# YTM32B1HA0 register map
Vendor: YTMicro; File version: 1.0
CPU: little endian, MPU, FPU, 2 interrupt priority bits
Registers are 32-bit, read-write, reset 0x0 unless marked. A register's access mark holds for its fields unless they carry their own. Offsets are from the block's base; [hi:lo] are bit positions; {n}, {i} and the like mark numbered series; 'fields as' and 'values as' point back to an identical list.

## LINFlexD0
Base 0x4006C000; register names take the prefix LINFlexD0_
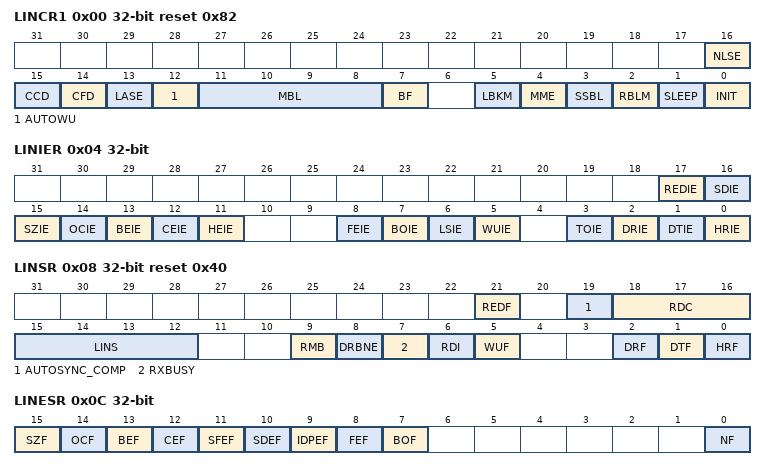
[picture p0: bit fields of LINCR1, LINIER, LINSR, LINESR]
0x00 LINCR1 reset 0x82 — The LINCR1 register consists of control bits used to configure features of the LINFlexD. ote{When accessing the LINCR1 register, each reserved bit should be written with its original reset value.}
  [16] NLSE — NLSE enables/disables capture of the LIN state (LINSR.LINS) whenever a bit error flag occurs (LINESR.BEF is set to 1).
    0=LINSR.LINS shows the current LIN state and does not capture the LIN state on bit error; 1=LINSR.LINS is captured when a bit error flag occurs
  [15] CCD
    0=Checksum calculation is done by hardware. The LINCFR register is read-only.; 1=Checksum calculation is disabled. The LINCFR register is read/write. If the checksum field is enabled (CFD = 0), LINCFR can be programmed to send a software-calculated checksum/CRC.
  [14] CFD
    0=Checksum field is sent after the required number of data bytes are sent; 1=No checksum field is sent in the frame
  [13] LASE — Enables the autosynchronization, feature described in “Automatic Resynchronization”.
    0=Disable autosynchronization; 1=Enable autosynchronization
  [12] AUTOWU
    0=The SLEEP bit is cleared by software only; 1=The SLEEP bit is cleared by hardware whenever the LINSR.WUF bit is set
  [11:8] MBL — Controls the length of the break field generated in LIN master mode.
    {v}={v+10}-bit break length (v=0..13); 14=36-bit break length; 15=50-bit break length
  [7] BF — Controls the receive filter bypass function.
    0=Receiver ignores incoming frame if ID does not match any ID filter or if no ID filters are active; 1=If no ID filters are active, receiver responds to incoming frames. If ID filters are active, receiver responds if frame is received but does not match any filter.
  [5] LBKM — Enables or disables Loop Back mode as described in “Loop Back Mode”.
    0=Disable Loop Back mode; 1=Enable Loop Back mode
  [4] MME
    0=Slave mode; 1=Master mode
  [3] SSBL — Sets the number of bit times for break field detection in slave mode.
    0=11-bit break length; 1=10-bit break length
  [2] RBLM
    0=Receiver is buffer is not locked. The next incoming message overwrites the previous one.; 1=Receiver buffer is locked against overrun. Once the buffer is full, the next incoming message is discarded if the buffer is not released by software clearing the LINSR.RMB bit.
  [1] SLEEP — Set by software to request LINFlexD to enter Sleep mode. ewline The SLEEP bit is cleared by software to exit sleep mode. ewline If LINCR1.AUTOWU and LINSR.WUF are set, SLEEP is automatically cleared by hardware to exit sleep mode. ewline SLEEP is effective in both LIN and UART modes.
  [0] INIT — Set by software to switch the hardware into Initialization mode. ewline When software clears the INIT bit (and if the SLEEP bit is also 0), the LINFlexD enters Normal mode. ewline INIT is effective in both LIN and UART modes.
0x04 LINIER
  [17] REDIE
    0=Interrupt disabled; 1=Interrupt enabled. An interrupt is generated when the Receive Edge Detection Flag (REDF) is set in LINSR.
  [16] SDIE
    0=Interrupt disabled; 1=Interrupt enabled. An interrupt is generated when the Start Detection Flag (SDF) is set in LINSR.
  [15] SZIE
    0=Interrupt disabled; 1=Interrupt enabled. An interrupt is generated when the Stuck at Zero Flag (SZF) is set in LINESR or UARTSR.
  [14] OCIE
    0=Interrupt disabled; 1=Interrupt enabled. An interrupt is generated when the Output Compare Flag (OCF) is set in LINESR or UARTSR.
  [13] BEIE
    0=Interrupt disabled; 1=Interrupt enabled. An interrupt is generated when the Bit Error Flag (BEF) is set in LINESR.
  [12] CEIE
    0=Interrupt disabled; 1=Interrupt enabled. An interrupt is generated when the Checksum Error Flag (CEF) is set in LINESR.
  [11] HEIE
    0=Interrupt disabled; 1=Interrupt enabled. An interrupt is generated when the any of the following flags are set in LINESR: SFEF, SDEF, IDPEF.
  [8] FEIE
    0=Interrupt disabled; 1=Interrupt enabled. An interrupt is generated when the Frame Error Flag (FEF) is set in LINESR or UARTSR.
  [7] BOIE
    0=Interrupt disabled; 1=Interrupt enabled. An interrupt is generated when the Buffer Overrun Flag (BOF) is set in LINESR or UARTSR.
  [6] LSIE
    0=Interrupt disabled; 1=Interrupt enabled. An interrupt generated on entering the following states: Sync Del, Sync Field, Identifier Field, Checksum.
  [5] WUIE
    0=Interrupt disabled; 1=Interrupt enabled. An interrupt generated when the Wakeup Flag (WUF) is set in LINESR or UARTSR.
  [3] TOIE
    0=Interrupt disabled; 1=Interrupt enabled. An interrupt generated when the LINFlexD is in UART mode and the Timeout bit (TO) is set in UARTSR.
  [2] DRIE
    0=Interrupt disabled; 1=Interrupt enabled. An interrupt generated when the Data Received Flag (DRF) is set in LINESR or UARTSR.
  [1] DTIE
    0=Interrupt disabled; 1=Interrupt enabled. An interrupt generated when the Data Transmitted Flag (DTF) is set in LINESR or UARTSR.
  [0] HRIE
    0=Interrupt disabled; 1=Interrupt enabled. An interrupt is generated Header Received Flag (HRF) is set in LINSR.
0x08 LINSR reset 0x40 — The LINSR register contains status bits indicating the state of the LINFlexD hardware. ote{Reset value of RDI reflects the LINFlexD_RX pin state.}
  [21] REDF — REDF is set by hardware when receiving falling edge is detected.
  [19] AUTOSYNC_COMP — AUTOSYNC_COMP is set when autosynchronization is enabled (LINCR1.LASE is set) and autosynchronization is complete. After AUTOSYNC_COMP is set, the contents of LINIBRR and LINFBRR registers can be read.
  [18:16] RDC ro — RDC contains the number of entries (bytes) in the receive data buffer in LIN mode.
    0=1 byte; {v}={v+1} bytes (v=1..7)
  [15:12] LINS ro
  [9] RMB
    0=Buffer is free; 1=Buffer data is ready to be read by software. RMB should be cleared by software after reading the data received in the buffer.
  [8] DRBNE — DRBNE is set by hardware as soon as the first byte of response is received and stored in DATA (when there is at least one data byte in reception buffer). Software should clear DRBNE after reading all the buffers. ewline DRBNE can be checked by software in the case of a response timeout event. ewline DRBNE is cleared by hardware in Initialization mode.
  [7] RXBUSY ro
    0=Receiver is idle; 1=Reception is ongoing
  [6] RDI ro — Indicates the current state of the LINFlexD_RX pin. ote{After reset is released, RDI reflects the actual value of the LINFlexD_RX pin.}
  [5] WUF — WUF is set by hardware when a falling edge is detected on the LINFlexD_RX pin in either of the following conditions: \begin{itemize}[] \item The LINFlexD is in slave mode and in Sleep mode. \item The LINFlexD is in master mode is in either Sleep mode or Idle state. \end{itemize} WUF is cleared by hardware in Initialization mode.
  [2] DRF — DRF is set by hardware and indicates that data reception has completed. ewline DRF is cleared by hardware in Initialization mode. ote{DRF is not set when a framing error or checksum error occurs.}
  [1] DTF — DTF is set by hardware and indicates that data transmission has completed. ewline DTF is cleared by hardware in Initialization mode. ote{DTF is not set in LIN mode when a bit error occurs and LINCR2.IOBE = 0.}
  [0] HRF — HRF is set by hardware when header reception completes and one of the following conditions is true. \begin{itemize}[] \item All filters are inactive and LINCR1.BF = 1. \item No match in any filter and LINCR1.BF = 1. \item Tx filter match. \end{itemize} HRF is reset by hardware in Initialization mode and at end of completed or aborted frame.
0x0C LINESR — The LINESR register contains status bits for various error conditions. For detailed descriptions the error conditions, see \hyperlink{errors}{“Errors”}.
  [15] SZF — Set by hardware when a stuck-at-zero timeout error occurs.
  [14] OCF — In master mode, OCF is set when counter LINTCSR.CNT matches the content of LINOCR.OC2. ewline In slave mode, OCF is set when the content of the counter LINTCSR.CNT matches the content of LINOCR.OC1 or LINOCR.OC2. ewline If OCF is set when LINTCSR.MODE = 0 and LINTCSR.IOT = 1, the LINFlexD goes to Idle state. ewline When LINTCSR.MODE = 0, OCF is cleared by hardware in Initialization mode. ewline When LINTCSR.MODE = 1, OCF maintains its status regardless of the LIN state.
  [13] BEF — BEF is set by hardware when the LINFlexD detects a bit error. ewline BEF is cleared by hardware in Initialization mode.
  [12] CEF — CEF is set by hardware when the received checksum does not match the hardware calculated checksum. ewline CEF is cleared by hardware in Initialization mode. ote{CEF is never set if LINCR1.CCD or LINCR1.CFD is set.}
  [11] SFEF — SFEF is set by hardware when a sync field error occurs due to an inconsistent sync field. ewline SFEF is cleared by hardware in Initialization mode.
  [10] SDEF — SDEF is set by hardware when a break delimiter error occurs because a break delimiter is too short (less than one bit time). ewline SDEF is cleared by hardware in Initialization mode.
  [9] IDPEF — IDPEF is set by hardware LINFlexD detects an error in the ID parity. ewline IDPEF is cleared by hardware in Initialization mode.
  [8] FEF — FEF is set by hardware when a framing error (invalid stop bit) occurs. ewline FEF is cleared by hardware in Initialization mode.
  [7] BOF — BOF is set by hardware when a new byte is received and LINSR.RMB bit is not cleared. ewline BOF is cleared by hardware in Initialization mode.
  [0] NF — NF is set by hardware when noise is detected in a receive character. ewline NF is cleared by hardware in Initialization mode.
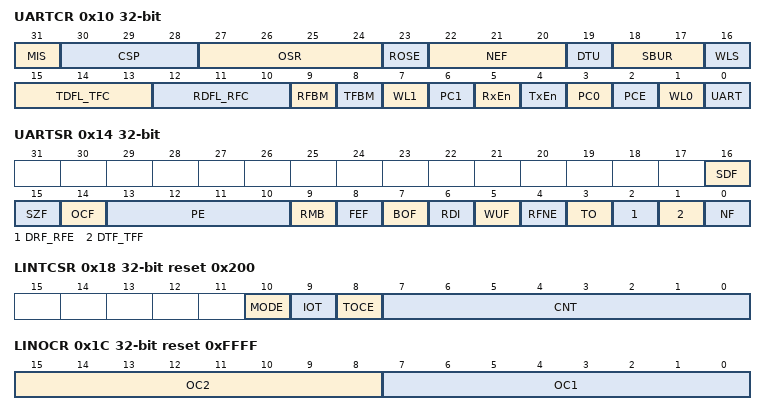
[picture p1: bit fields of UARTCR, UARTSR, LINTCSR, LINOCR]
0x10 UARTCR — The UARTCR register contains control bits for UART mode. ote{Always write ‘0’ to reserved bits when writing to UARTCR.} ote{In UART mode, the LINFlexD does not support communication with Special Word Length (UARTCR.WLS = 1) in buffer mode.} ote{In UART mode, the LINFlexD supports communication with Special Word Length (UARTCR.WLS = 1) in FIFO mode only with UARTCR.WL[1:0] = 11.}
  [31] MIS
    0=UARTCTO monitors the number of bits to be received; 1=UARTCTO monitors the idle state of the reception line
  [30:28] CSP — The CSP bits select the sample point during reduced oversampling. ewline CSP can have the following range of values for the specified oversampling rate:
  [27:24] OSR — Selects the number of samples taken for a bit when reduced oversampling is enabled. ewline The values allowed for OSR are 4, 5, 6, and 8. ote{When idle state monitoring is enabled (MIS = 1), the allowed OSR values are 4 and 8.} OSR can be read in any mode, but can be written only during Initialization mode.
  [23] ROSE
    0=Each bit is oversampled sixteen times; 1=OSR bits determine the oversampling rate
  [22:20] NEF — The NEF bits set the number of expected frames in UART reception mode. If the DTU bit is set, then the UART timeout counter is reset after the configured number of frames have been received. ewline NEF can be read in any mode, but can be written only during Initialization mode.
  [19] DTU
    0=Timeout must be handled by software; 1=Timeout in UART mode is disabled after the configured number of data frames are received
  [18:17] SBUR
    0=1 stop bit; 1=2 stop bits; 2=3 stop bits
  [16] WLS
    0=Disable 12-bit + parity bit in reception; 1=Enable 12-bit + parity bit in reception (UART mode)
  [15:13] TDFL_TFC — The TDFL_TFC field has one of two functions depending on the mode of operation. ewline extbf{UART Buffer Mode:} ewline When the LINFlexD is in UART buffer mode (TFBM = 0), TDFL_TFC is read/write and defines the number of bytes to be transmitted. \begin{itemize}[] \item x00: 1 byte \item x01: 2 bytes \item x10: 3 bytes \item x11: 4 bytes \end{itemize} The first bit is reserved and not implemented. ewline When the UART data length is configured as half-word (WL = 10 or 11), the only valid values for TDFL_TFC are x01 and x11. ewline extbf{UART FIFO Mode:} ewline When the LINFlexD is in UART FIFO mode (TFBM = 1), TDFL_TFC is read-only and contains the number of entries (bytes) in the Tx FIFO. \begin{itemize}[] \item 000: Empty \item 001: 1 byte \item 010: 2 bytes \item 011: 3 bytes \item 100: 4 bytes \item All other values: Reserved \end{itemize} TDFL_TFC can be read in any mode, but can be written only during Initialization mode, when the UART bit is set.
  [12:10] RDFL_RFC — The RDFL_RFC field has one of two functions depending on the mode of operation. ewline extbf{UART Buffer Mode:} ewline When the LINFlexD is in UART buffer mode (RFBM = 0), RDFL_RFC is read/write and defines the number of bytes to be received: \begin{itemize}[] \item x00: 1 byte \item x01: 2 bytes \item x10: 3 bytes \item x11: 4 bytes \end{itemize} The first bit is reserved and not implemented. ewline When the UART data length is configured as half-word (WL = 10 or 11), the only valid values for RDFL_RFC are x01 and x11. ewline RDFL_RFC should be programmed to be greater than or equal to NEF (number of expected frames). ewline extbf{UART FIFO Mode:} ewline When the LINFlexD is in UART FIFO mode (RFBM = 1), RDFL_RFC is read-only and contains the number of entries (bytes) in the Rx FIFO: \begin{itemize}[] \item 000: Empty \item 001: 1 byte \item 010: 2 bytes (1.5 byte if WLS = 1) \item 011: 3 bytes \item 100: 4 bytes (2x1.5 bytes if WLS = 1) \item All other values: Reserved \end{itemize} RDFL_RFC can be read in any mode, but can be written only during Initialization mode, when the UART bit is set.
  [9] RFBM
    0=Rx buffer mode enabled; 1=Rx FIFO mode enabled (mandatory in DMA Rx mode)
  [8] TFBM
    0=Tx buffer mode enabled; 1=Tx FIFO mode enabled (mandatory in DMA Tx mode)
  [7] WL1
  [6] PC1
  [5] RxEn
    0=Receiver disabled; 1=Receiver enabled
  [4] TxEn
    0=Transmitter disabled; 1=Transmitter enabled
  [3] PC0
  [2] PCE
    0=Parity transmit/check disabled; 1=Parity transmit/check enabled
  [1] WL0
  [0] UART
    0=LIN mode; 1=UART mode
0x14 UARTSR — The UARTSR register contains status bits for UART mode.
  [16] SDF — SDF is set by hardware when receiving start bit is detected.
  [15] SZF — SZF is set by hardware when 100 dominant bits are detected. An interrupt is generated if LINIER.SZIE = 1. ewline SZF reflects the same value as LINESR.SZF when the LINFlexD is not in Initialization mode and UARTCR.UART = 1.
  [14] OCF
    0=No output compare event occurred; 1=The content of the timeout counter matched the content of LINOCR
  [13:10] PE — Indicates parity error in corresponding receive data byte.
    0=No parity error detected; 1=Parity error detected
  [9] RMB
    0=Buffer is free; 1=Buffer data is ready to be read by software
  [8] FEF — FEF is set by hardware when the LINFlexD detects a framing error (invalid stop bit). An interrupt is generated if LINIER.FEIE = 1. ewline FEF reflects the same value as LINESR.FEF when the LINFlexD is not in Initialization mode and UARTCR.UART = 1.
  [7] BOF — In UART buffer mode, BOF is set by hardware when there is a new byte received and the RMB bit is not cleared. If LINCR.RBLM = 1, the newly received message is discarded. If LINCR.RBLM = 0, the newly received message overwrites the buffer. ewline In UART FIFO mode, BOF is set when there is a new byte received and the Rx FIFO is full. In UART FIFO mode, once Rx FIFO is full, the new received message is discarded regardless of the value of the RBLM bit. ewline When BOF is set, an interrupt is generated if LINIER.BOIE = 1. ewline BOF reflects the same value as LINESR.BOF when the LINFlexD is not in Initialization mode and UARTCR.UART = 0.
  [6] RDI ro — Reflects the current state of the LINFlexD_RX pin when UARTCR.UART = 1
  [5] WUF — WUF is set by hardware when a falling edge is detected on the LINFlexD_RX pin in Sleep mode. An interrupt is generated if LINIER.WUIE = 1. ewline WUF reflects the same value as LINSR.WUF when the LINFlexD is not in Initialization mode and UARTCR.UART = 1.
  [4] RFNE ro — RFNE is set by hardware in UART FIFO mode (RFBM = 1), when there is at least one data byte present in the receive FIFO. RFNE is a read-only bit for debugging purposes. ewline RFNE can be used by software in case of a timeout event.
  [3] TO — TO is set by hardware when a UART timeout occurs — in other words, the value of UARTCTO becomes equal to the preset value of the timeout (UARTPTO register setting). An interrupt is generated if LINIER.TOIE = 1. ewline The GCR.SR bit should be used to reset the receiver FSM to the Idle state in the event of timeout for UART reception in both UART buffer and UART FIFO modes.
  [2] DRF_RFE — The DRF_RFE bit function depends on whether the LINFlexD is operating in UART buffer mode or UART FIFO mode. ewline extbf{UART Buffer Mode:} ewline In UART buffer mode (RFBM = 0), the DRF (data received flag) function of DRF_RFE is used. DRF is set by hardware in UART buffer mode when the number of bytes programmed in UARTCR.RDFL are received. An interrupt is generated if LINIER.DRIE = 1. ewline DRF is set when the configured number of valid stop bits are received for the last frame. ewline DRF is set regardless of parity error, overrun error, or framing error if the framing error is in the last STOP bit configured. ewline DRF reflects the same value as LINSR.DRF when the LINFlexD is not in Initialization mode and UARTCR.UART = 1. ewline DRF can be read/cleared by software. Writing ‘1’ clears DRF. ewline extbf{UART FIFO Mode:} ewline In UART FIFO mode (RFBM = 1), the RFE (Rx FIFO empty) function of DRF_RFE is used. RFE is set by hardware in UART FIFO mode when the Rx FIFO is empty. ewline RFE is a read-only bit for debugging purposes. It is internally used by the DMA Rx interface.
  [1] DTF_TFF — The DTF_TFF bit function depends on whether the LINFlexD is operating in UART buffer mode or UART FIFO mode. ewline extbf{UART Buffer Mode:} ewline In UART buffer mode (RFBM = 0), the DTF (data transmitted flag) function of DTF_TFF is used. DTF is set by hardware in UART buffer mode when data transmission completes. An interrupt is generated if LINIER.DTIE = 1. ewline DTF reflects the same value as LINSR.DTF when the LINFlexD is not in Initialization mode and UARTCR.UART = 1. ewline DTF can be read/cleared by software. Writing ‘1’ clears DTF. ewline extbf{UART FIFO Mode:} ewline In UART FIFO mode (RFBM = 1), the TFF (Tx FIFO full) function of DTF_TFF is used. TFF is set by hardware in UART FIFO mode when Tx FIFO is full. ewline TFF is a read-only bit for debugging purposes. It is internally used by the DMA Tx interface.
  [0] NF — Set by hardware when noise is detected in the received character. ewline NF reflects the same value as LINESR.NF when the LINFlexD is not in Initialization mode and the UARTCR.UART = 1. ewline During reduced oversampling (UARTCR.ROSE = 1), the NF bit is enabled only when UARTCR.OSR = 8.
0x18 LINTCSR reset 0x200 — The LINTCSR register contains control and status bits for the LIN timeout feature. ote{When LINTCSR.MODE = 0, any activity on the transmit or receive pins will cause an unwanted change in the value of the 8-bit field Output Compare Value 2 (OC2) of the LIN Output Compare register (LINOCR). If the LINFlexD is enabled in LIN mode and the value of LINTCSR.MODE is changed from ‘1’ to ‘0’, the old values of LINOCR.OC1 and LINOCR.OC2 are retained. As a consequence, if the LINFlexD is reconfigured from UART mode to LIN mode, or LINTCSR.MODE is changed from ‘1’ to ‘0’, an incorrect timeout exception is generated when a LIN communication starts. To avoid this, set LINTCSR.MODE to ‘1’, reconfigure the LINFlexD in LIN mode, then reset LINTCSR.MODE to ‘0’. Before switching LINTCSR.MODE from ‘1’ to ‘0’ between frames, load LINOCR with 0xFFFF.}
  [10] MODE
    0=LIN mode; 1=Output compare mode
  [9] IOT
    0=LIN state machine does not reset to Idle on timeout; 1=LIN state machine resets to Idle on timeout event
  [8] TOCE
    0=Timeout counter disabled. UARTSR.OCF flag is not set on an output compare event.; 1=Timeout counter enabled. UARTSR.OCF is set if an output compare event occurs.
  [7:0] CNT ro — The value of the timeout counter. ote{For proper functionality of this counter, LINIBRR should be greater than or equal to 5.}
0x1C LINOCR reset 0xFFFF — The LINOCR register contains the value to be compared to the LINTCSR.CNT value. ewline LINOCR is writable by software only in when the counter is in output compare mode.
  [15:8] OC2, [7:0] OC1
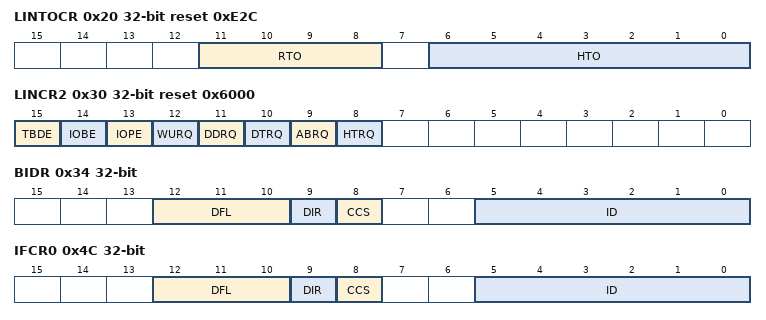
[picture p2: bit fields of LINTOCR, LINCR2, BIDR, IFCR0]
0x20 LINTOCR reset 0xE2C — The LINTOCR register contains the LIN mode response and header timeout values.
  [11:8] RTO
  [6:0] HTO — HTO specifies the header timeout duration (in bit time). HTO can be written only for slave mode. The header timeout should be programmed without considering 11 bits of break field.
0x24 LINFBRR — LINFBRR sets the fractional part of the LIN baud rate, as described in \hyperlink{baud-rate-generation}{“Baud Rate Generation”}. ote{When LINCR1.LASE = 1, LINFBRR should be read only after LINSR.AUTOSYNC_COMP is set to obtain the correct value.} ote{LINFBRR cannot be used when reduced oversampling is enabled (UARTCR.ROSE = 1).}
  [3:0] FBR
    0=Fraction(LDIV) = 0; {v}=Fraction(LDIV) = {v}/16 (v=1..15)
0x28 LINIBRR — LINIBRR sets the integer part of the LIN baud rate, as described in \hyperlink{baud-rate-generation}{“Baud Rate Generation”}. ote{When LINCR1.LASE = 1, LINIBRR should be read only after LINSR.AUTOSYNC_COMP is set to obtain the correct value.}
  [19:0] IBR — The IBR bits, along with the fractional baud rate bits in LINFBRR, set the LIN baud rate. \begin{itemize}[] \item IBR = 0x0: LIN clock disabled \item IBR = 0x1: Mantissa(LDIV) = 1 \item ... \item IBR = 0xFFFFE: Mantissa(LDIV) = 1048574 \item IBR = 0xFFFFF: Mantissa(LDIV) = 1048575 \end{itemize} IBR can be read in any mode, but can be written only during Initialization mode.
0x2C LINCFR — ote{There is a delay between 4 to 6 clock cycles of bus clock for the internal checksum’s value (which is clocked with ipg_baud_clk/16 * LDIV) to reflect on LINCFR.} ote{Due to synchronization structures between the two input clocks to the LINFlexD, the write to this register is delayed between 2 to 3 clock cycles of bus clock.}
  [7:0] CF — When LINCR1.CCD = 0, the CF bits are read-only and are calculated by hardware. ewline When LINCR1.CCD = 1, the CF bits can be written by software.
0x30 LINCR2 reset 0x6000 — The LINCR2 register contains control and status bits related to buffer operations. ote{When accessing LINCR2, each reserved bit should be written with its original reset value.}
  [15] TBDE
    0=Delimiter length in break field is 1 bit; 1=Delimiter length in break field is 2 bits
  [14] IOBE
    0=Bit error does not reset LIN state machine; 1=Bit error resets LIN state machine
  [13] IOPE
    0=Parity error does not reset LIN state machine; 1=Parity error resets LIN state machine
  [12] WURQ — Setting WURQ generates a wakeup request. The character sent during wakeup is copied from DATA0. WURQ is reset by hardware when the wakeup character has been transmitted. ewline WURQ cannot be set in Sleep mode. Software must exit Sleep mode before setting WURQ. ewline Bit error is not checked when transmitting the wakeup request.
  [11] DDRQ — DDRQ is set by software to stop data reception if the frame does not concern the node. DDRQ is reset by hardware once the LINFlexD ignores the response and moves to Idle state. ewline For a LIN slave, DDRQ can be set only when LINSR.HRF = 1 and the identifier is software-filtered.
  [10] DTRQ — DTRQ is set by software in slave mode to request the transmission of the LIN data field stored in the buffer data register. DTRQ can be set only when LINSR.HRF = 1 (to ensure that data transmission is requested only after a header reception). ewline DTRQ is cleared by hardware when the request has been completed, or on abort request or error condition. ewline In master mode, DTRQ is set by hardware when BIDR.DIR = 1 and header transmission is complete.
  [9] ABRQ — ABRQ is set by software to abort the current transmission. The LINFlexD aborts the transmission at the end of the current bit. ewline ABRQ is cleared by hardware when the transmission has been aborted. ewline ABRQ can abort a wakeup request and can also be used in UART mode.
  [8] HTRQ — HTRQ is set by software to request the transmission of a LIN header. ewline HTRQ is cleared by hardware when the request has been completed or on abort request. ewline HTRQ has no effect in UART mode. ote{In master mode, if both HTRQ and ABRQ are set at the same time then ABRQ has no effect. Similarly, in slave mode after header reception, if DTRQ and ABRQ are simultaneously set then ABRQ has no effect.}
0x34 BIDR — The BIDR register contains bits that provide information about the identifier of the transaction and other related information. ote{All the fields (ID, CSS, DIR, DFL) of the BIDR register must be updated when an ID filter (enabled) in Slave mode (Tx or Rx) matches the ID received.}
  [12:10] DFL — Number of data bytes in the response part of the frame. ewline DFL = Number of data bytes - 1.
  [9] DIR — Controls the direction of the data field.
    0=LINFlexD receives the data and copies it to the DATA registers; 1=LINFlexD transmits the data from the DATA registers
  [8] CCS — Controls the type of checksum applied on the current message.
    0=Enhanced checksum covering identifier and data fields. This is compatible with LIN specification rev. 2.0 and higher.; 1=Classic checksum covering data field only. This is compatible with LIN specification rev. 1.3 and lower.
  [5:0] ID — Identifier part of the identifier field without the identifier parity. ewline The ID field can be written only in master mode (LINCR1.MME = 1).
0x38 DATA8 8-bit
  [7:0] DATA — Byte of the data field.
0x40 IFER — The IFER register enables/disables the identifier filters. There is one filter active (FACT) bit for each filter.
  [15:0] FACT — One bit for each identifier filter. ewline Software sets FACT[n] to activate the filter n in identifier list mode. ewline In identifier mask mode, FACT[2n+1] have no effect on the corresponding filters as they act as mask for identifier 2n. ewline FACT[n] can be read in any mode, but can be written only during Initialization mode.
0x44 IFMI ro — The IFMI register contains the index corresponding to the received identifier. It can be used to read or write the data directly in RAM.
  [4:0] IFMI — Contains the index corresponding to the received identifier. ewline Upon a filter match with filter x, IFMI[N:0] = x+1. ewline On no match, IFMI is equal to 0x00. ewline IFMI can be used to directly write or read the data in RAM (see \hyperlink{slave-mode}{“Slave Mode”} for details).
0x48 IFMR — The IFMR register configures the modes of filters. There is one IFM bit for each pair of filters.
  [7:0] IFM — \begin{itemize}[] \item 0: Filters 2n and 2n+1 are in identifier list mode. \item 1: Filters 2n and 2n+1 are in mask mode. Filter 2n+1 is the mask for filter 2n. \end{itemize} IFM[n] can be read in any mode, but can be written only during Initialization mode.
0x4C IFCR0 — There is an Identifier Filter Control Register (IFCRn) for each filter. ewline Even-numbered instances of IFCRn (IFCR0, IFCR2, IFCR4, and so on) act as filters in both identifier list and identifier mask modes. ewline Odd-numbered instances of IFCRn (IFCR1, IFCR3, IFCR5, and so on) act as: \begin{itemize}[] \item Filters in identifier list mode. \item A mask for the preceding-numbered register in identifier mask mode. For example, if filters 0 and 1 are configured for identifier mask mode, IFCR1 acts as a mask for IFCR0. \end{itemize} The IFCRn registers are read-only in Normal mode and can be written only in Initialization mode.
  [12:10] DFL — Number of data bytes in the response part of the frame. ewline DFL = Number of data bytes - 1.
  [9] DIR — Controls the direction of the data field.
    0=LINFlexD receives the data and copy it to the DATA registers; 1=LINFlexD transmits the data from the DATA register
  [8] CCS — Controls the type of checksum applied on the current message.
    values as BIDR.CCS
  [5:0] ID — Identifier part of the identifier field without the identifier parity.
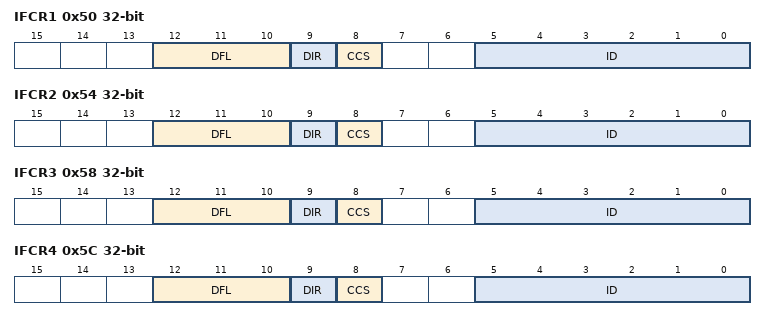
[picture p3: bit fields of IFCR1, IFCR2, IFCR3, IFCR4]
0x50 IFCR1 — There is an Identifier Filter Control Register (IFCRn) for each filter. ewline Even-numbered instances of IFCRn (IFCR0, IFCR2, IFCR4, and so on) act as filters in both identifier list and identifier mask modes. ewline Odd-numbered instances of IFCRn (IFCR1, IFCR3, IFCR5, and so on) act as: \begin{itemize}[] \item Filters in identifier list mode. \item A mask for the preceding-numbered register in identifier mask mode. For example, if filters 0 and 1 are configured for identifier mask mode, IFCR1 acts as a mask for IFCR0. \end{itemize} The IFCRn registers are read-only in Normal mode and can be written only in Initialization mode.
  fields as IFCR0
0x54 IFCR2 — There is an Identifier Filter Control Register (IFCRn) for each filter. ewline Even-numbered instances of IFCRn (IFCR0, IFCR2, IFCR4, and so on) act as filters in both identifier list and identifier mask modes. ewline Odd-numbered instances of IFCRn (IFCR1, IFCR3, IFCR5, and so on) act as: \begin{itemize}[] \item Filters in identifier list mode. \item A mask for the preceding-numbered register in identifier mask mode. For example, if filters 0 and 1 are configured for identifier mask mode, IFCR1 acts as a mask for IFCR0. \end{itemize} The IFCRn registers are read-only in Normal mode and can be written only in Initialization mode.
  fields as IFCR0
0x58 IFCR3 — There is an Identifier Filter Control Register (IFCRn) for each filter. ewline Even-numbered instances of IFCRn (IFCR0, IFCR2, IFCR4, and so on) act as filters in both identifier list and identifier mask modes. ewline Odd-numbered instances of IFCRn (IFCR1, IFCR3, IFCR5, and so on) act as: \begin{itemize}[] \item Filters in identifier list mode. \item A mask for the preceding-numbered register in identifier mask mode. For example, if filters 0 and 1 are configured for identifier mask mode, IFCR1 acts as a mask for IFCR0. \end{itemize} The IFCRn registers are read-only in Normal mode and can be written only in Initialization mode.
  fields as IFCR0
0x5C IFCR4 — There is an Identifier Filter Control Register (IFCRn) for each filter. ewline Even-numbered instances of IFCRn (IFCR0, IFCR2, IFCR4, and so on) act as filters in both identifier list and identifier mask modes. ewline Odd-numbered instances of IFCRn (IFCR1, IFCR3, IFCR5, and so on) act as: \begin{itemize}[] \item Filters in identifier list mode. \item A mask for the preceding-numbered register in identifier mask mode. For example, if filters 0 and 1 are configured for identifier mask mode, IFCR1 acts as a mask for IFCR0. \end{itemize} The IFCRn registers are read-only in Normal mode and can be written only in Initialization mode.
  fields as IFCR0
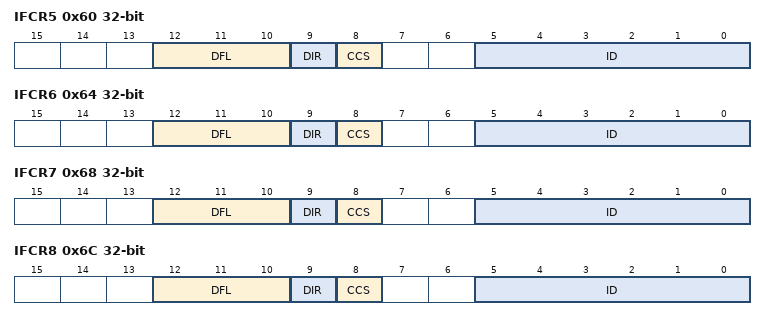
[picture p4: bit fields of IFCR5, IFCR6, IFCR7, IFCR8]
0x60 IFCR5 — There is an Identifier Filter Control Register (IFCRn) for each filter. ewline Even-numbered instances of IFCRn (IFCR0, IFCR2, IFCR4, and so on) act as filters in both identifier list and identifier mask modes. ewline Odd-numbered instances of IFCRn (IFCR1, IFCR3, IFCR5, and so on) act as: \begin{itemize}[] \item Filters in identifier list mode. \item A mask for the preceding-numbered register in identifier mask mode. For example, if filters 0 and 1 are configured for identifier mask mode, IFCR1 acts as a mask for IFCR0. \end{itemize} The IFCRn registers are read-only in Normal mode and can be written only in Initialization mode.
  fields as IFCR0
0x64 IFCR6 — There is an Identifier Filter Control Register (IFCRn) for each filter. ewline Even-numbered instances of IFCRn (IFCR0, IFCR2, IFCR4, and so on) act as filters in both identifier list and identifier mask modes. ewline Odd-numbered instances of IFCRn (IFCR1, IFCR3, IFCR5, and so on) act as: \begin{itemize}[] \item Filters in identifier list mode. \item A mask for the preceding-numbered register in identifier mask mode. For example, if filters 0 and 1 are configured for identifier mask mode, IFCR1 acts as a mask for IFCR0. \end{itemize} The IFCRn registers are read-only in Normal mode and can be written only in Initialization mode.
  fields as IFCR0
0x68 IFCR7 — There is an Identifier Filter Control Register (IFCRn) for each filter. ewline Even-numbered instances of IFCRn (IFCR0, IFCR2, IFCR4, and so on) act as filters in both identifier list and identifier mask modes. ewline Odd-numbered instances of IFCRn (IFCR1, IFCR3, IFCR5, and so on) act as: \begin{itemize}[] \item Filters in identifier list mode. \item A mask for the preceding-numbered register in identifier mask mode. For example, if filters 0 and 1 are configured for identifier mask mode, IFCR1 acts as a mask for IFCR0. \end{itemize} The IFCRn registers are read-only in Normal mode and can be written only in Initialization mode.
  fields as IFCR0
0x6C IFCR8 — There is an Identifier Filter Control Register (IFCRn) for each filter. ewline Even-numbered instances of IFCRn (IFCR0, IFCR2, IFCR4, and so on) act as filters in both identifier list and identifier mask modes. ewline Odd-numbered instances of IFCRn (IFCR1, IFCR3, IFCR5, and so on) act as: \begin{itemize}[] \item Filters in identifier list mode. \item A mask for the preceding-numbered register in identifier mask mode. For example, if filters 0 and 1 are configured for identifier mask mode, IFCR1 acts as a mask for IFCR0. \end{itemize} The IFCRn registers are read-only in Normal mode and can be written only in Initialization mode.
  fields as IFCR0
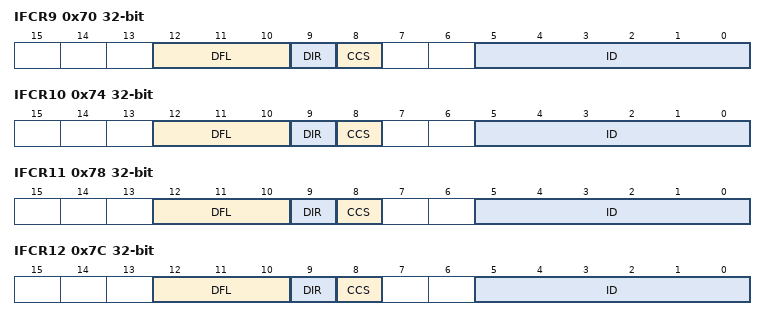
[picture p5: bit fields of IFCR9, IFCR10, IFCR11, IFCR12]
0x70 IFCR9 — There is an Identifier Filter Control Register (IFCRn) for each filter. ewline Even-numbered instances of IFCRn (IFCR0, IFCR2, IFCR4, and so on) act as filters in both identifier list and identifier mask modes. ewline Odd-numbered instances of IFCRn (IFCR1, IFCR3, IFCR5, and so on) act as: \begin{itemize}[] \item Filters in identifier list mode. \item A mask for the preceding-numbered register in identifier mask mode. For example, if filters 0 and 1 are configured for identifier mask mode, IFCR1 acts as a mask for IFCR0. \end{itemize} The IFCRn registers are read-only in Normal mode and can be written only in Initialization mode.
  fields as IFCR0
0x74 IFCR10 — There is an Identifier Filter Control Register (IFCRn) for each filter. ewline Even-numbered instances of IFCRn (IFCR0, IFCR2, IFCR4, and so on) act as filters in both identifier list and identifier mask modes. ewline Odd-numbered instances of IFCRn (IFCR1, IFCR3, IFCR5, and so on) act as: \begin{itemize}[] \item Filters in identifier list mode. \item A mask for the preceding-numbered register in identifier mask mode. For example, if filters 0 and 1 are configured for identifier mask mode, IFCR1 acts as a mask for IFCR0. \end{itemize} The IFCRn registers are read-only in Normal mode and can be written only in Initialization mode.
  fields as IFCR0
0x78 IFCR11 — There is an Identifier Filter Control Register (IFCRn) for each filter. ewline Even-numbered instances of IFCRn (IFCR0, IFCR2, IFCR4, and so on) act as filters in both identifier list and identifier mask modes. ewline Odd-numbered instances of IFCRn (IFCR1, IFCR3, IFCR5, and so on) act as: \begin{itemize}[] \item Filters in identifier list mode. \item A mask for the preceding-numbered register in identifier mask mode. For example, if filters 0 and 1 are configured for identifier mask mode, IFCR1 acts as a mask for IFCR0. \end{itemize} The IFCRn registers are read-only in Normal mode and can be written only in Initialization mode.
  fields as IFCR0
0x7C IFCR12 — There is an Identifier Filter Control Register (IFCRn) for each filter. ewline Even-numbered instances of IFCRn (IFCR0, IFCR2, IFCR4, and so on) act as filters in both identifier list and identifier mask modes. ewline Odd-numbered instances of IFCRn (IFCR1, IFCR3, IFCR5, and so on) act as: \begin{itemize}[] \item Filters in identifier list mode. \item A mask for the preceding-numbered register in identifier mask mode. For example, if filters 0 and 1 are configured for identifier mask mode, IFCR1 acts as a mask for IFCR0. \end{itemize} The IFCRn registers are read-only in Normal mode and can be written only in Initialization mode.
  fields as IFCR0
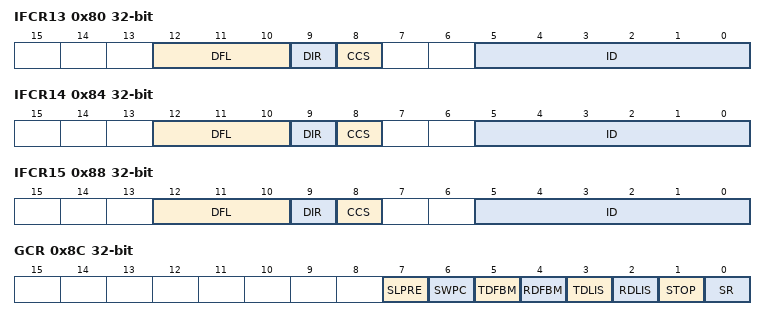
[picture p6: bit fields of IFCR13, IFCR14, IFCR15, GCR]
0x80 IFCR13 — There is an Identifier Filter Control Register (IFCRn) for each filter. ewline Even-numbered instances of IFCRn (IFCR0, IFCR2, IFCR4, and so on) act as filters in both identifier list and identifier mask modes. ewline Odd-numbered instances of IFCRn (IFCR1, IFCR3, IFCR5, and so on) act as: \begin{itemize}[] \item Filters in identifier list mode. \item A mask for the preceding-numbered register in identifier mask mode. For example, if filters 0 and 1 are configured for identifier mask mode, IFCR1 acts as a mask for IFCR0. \end{itemize} The IFCRn registers are read-only in Normal mode and can be written only in Initialization mode.
  fields as IFCR0
0x84 IFCR14 — There is an Identifier Filter Control Register (IFCRn) for each filter. ewline Even-numbered instances of IFCRn (IFCR0, IFCR2, IFCR4, and so on) act as filters in both identifier list and identifier mask modes. ewline Odd-numbered instances of IFCRn (IFCR1, IFCR3, IFCR5, and so on) act as: \begin{itemize}[] \item Filters in identifier list mode. \item A mask for the preceding-numbered register in identifier mask mode. For example, if filters 0 and 1 are configured for identifier mask mode, IFCR1 acts as a mask for IFCR0. \end{itemize} The IFCRn registers are read-only in Normal mode and can be written only in Initialization mode.
  fields as IFCR0
0x88 IFCR15 — There is an Identifier Filter Control Register (IFCRn) for each filter. ewline Even-numbered instances of IFCRn (IFCR0, IFCR2, IFCR4, and so on) act as filters in both identifier list and identifier mask modes. ewline Odd-numbered instances of IFCRn (IFCR1, IFCR3, IFCR5, and so on) act as: \begin{itemize}[] \item Filters in identifier list mode. \item A mask for the preceding-numbered register in identifier mask mode. For example, if filters 0 and 1 are configured for identifier mask mode, IFCR1 acts as a mask for IFCR0. \end{itemize} The IFCRn registers are read-only in Normal mode and can be written only in Initialization mode.
  fields as IFCR0
0x8C GCR — The GCR register contains control bits that apply to both LIN and UART modes. ewline The GCR register is read-only in Normal mode and can be written only in Initialization mode.
  [7] SLPRE — When this bit is set, the receiving data will be stored in LINFlexD buffer while the system is in sleep/deepsleep mode. It is valid only if LINFlexD is running (Normal mode) when system is in sleep/deepsleep mode.
  [6] SWPC — Controls the direction switch between ipp_ind_linrx and ipp_do_lintx.
    0=ipp_ind_linrx is working for reception, ipp_do_lintx is working for transmission; 1=ipp_ind_linrx is working for transmission, ipp_do_lintx is working for reception
  [5] TDFBM — Controls whether the first bit of transmit data (payload only) is the most or least significant bit from the respective buffer data register.
    0=The first bit of transmitted data is the least significant bit of the buffer data register (DATA0[0], DATA1[0], DATA2[0], DATA3[0], DATA4[0], DATA5[0], DATA6[0], DATA7[0]); 1=The first bit of transmitted data is the most significant bit of the buffer data register (DATA0[7], DATA1[7], DATA2[7], DATA3[7], DATA4[7], DATA5[7], DATA6[7], DATA7[7])
  [4] RDFBM — Controls whether the first bit of received data (payload only) is mapped to the most or least significant bit from the respective buffer data register.
    0=The first bit of received data is mapped to least significant bit of the buffer data register (DATA0[0], DATA1[0], DATA2[0], DATA3[0], DATA4[0], DATA5[0], DATA6[0], DATA7[0]); 1=The first bit of received data is mapped to the most significant bit of the buffer data register (DATA0[7], DATA1[7], DATA2[7], DATA3[7], DATA4[7], DATA5[7], DATA6[7], DATA7[7])
  [3] TDLIS — Controls the data inversion of transmitted data (payload only).
    0=Transmitted data is not inverted; 1=Transmitted data is inverted
  [2] RDLIS — Controls the data inversion of received data (payload only).
    0=Received data is not inverted; 1=Received data is inverted
  [1] STOP — Controls the number of stop bits transmitted for all fields (delimiter, sync, ID, checksum, payload).
    0=One stop bit; 1=Two stop bits
  [0] SR — Writing ‘1’ to SR executes a soft reset of the LINFlexD (FSMs, FIFO pointers, counters, timers, status and error registers) without modifying the configuration registers. SR should be cleared by software to perform further operations (SR is not cleared by hardware). ewline The SR bit can be written only be software in Initialization mode. The read value of SR is always ‘0’. ewline When writing ‘1’ to SR, below register fields are reset:
0x90 UARTPTO reset 0xFFF — The UARTPTO register contains the preset value of the timeout register in UART mode and is programmed according to the number of bits to be received or to monitor the idle state of the reception line. The UARTPTO register can be written by software at any time.
  [11:0] PTO — PTO defines the preset value of timeout counter. A zero value is forbidden; otherwise, the UARTSR[TO] status bit is immediately set.
0x94 UARTCTO ro — The UARTCTO register contains the current timeout value in UART mode. UARTCTO is used with the UARTPTO register to monitor the number of bits received by UART or to monitor the idle state of the reception line. ewline UART timeout works in both CPU and DMA modes. ewline The timeout counter: \begin{itemize}[] \item Starts at zero and counts upward. \item Is clocked with ipg_baud_clk / (16 * LDIV) synchronized to bus clock (when UARTCR.ROSE = 0). \item Is clocked with ipg_baud_clk / (UARTCR.OSR * LINIBRR.IBR) synchronized to bus clock (when UARTCR.ROSE = 1). \item Is automatically enabled when UARTCR.RXEN = 1. \end{itemize} ote{Due to synchronization, there is a delay between 4 to 6 clock cycles of bus clock for the internal value (which is clocked with ipg_baud_clk/16 * LDIV) to reflect on UARTCTO.} ewline The timeout counter is reset when one of the following conditions occurs: \begin{itemize}[] \item The number of frames received is equal to UARTCR.NEF. \item UARTCTO becomes equal to UARTPTO. \item UARTPTO is written. \item UARTSR.DRF is set and UARTCR.DTU = 1. \end{itemize} ewpage
  [11:0] CTO — CTO defines the current value of the timeout counter. CTO is a read-only field. CTO is reset every time UARTPTO is written, or UARTCTO = UARTPTO, or by hard/soft reset. When the CTO value matches the preset value (UARTPTO.PTO), the status bit UARTSR.TO is set.
0x98 DMATXE — The DMATXE register enables the DMA Tx interface. The DMATXE register can be written by software at any time. When DMATXE = 0x0000_0000, the DMA Tx interface FSM is forced (by soft reset) into the Idle state. ote{When configuration parameter DMA_SUPPORTED = 0, the LINFlexD does not support DMA operation. The DMATXE register is invalid and must be written only with value 0x0000_0000.}
  [15:0] DTE — \begin{itemize}[] \item 0 = DMA Tx channel n is disabled. \item 1 = DMA Tx channel n is enabled. \end{itemize}
0x9C DMARXE — The DMARXE register enables the DMA Rx interface. The DMARXE register can be written by software at any time. When DMARXE = 0x0000_0000, the DMA Rx interface FSM is forced (by soft reset) into the Idle state. ote{When configuration parameter DMA_SUPPORTED = 0, the LINFlexD does not support DMA operation. The DMARXE register is invalid and must be written only with value 0x0000_0000.}
  [15:0] DRE — \begin{itemize}[] \item 0 = DMA Rx channel n is disabled. \item 1 = DMA Rx channel n is enabled. \end{itemize}

## LINFlexD1
Base 0x40070000; register names take the prefix LINFlexD1_
Registers as LINFlexD0.

## LINFlexD2
Base 0x40074000; register names take the prefix LINFlexD2_
Registers as LINFlexD0.

## LINFlexD3
Base 0x40078000; register names take the prefix LINFlexD3_
Registers as LINFlexD0.

## LINFlexD4
Base 0x4007C000; register names take the prefix LINFlexD4_
Registers as LINFlexD0.

## LINFlexD5
Base 0x40080000; register names take the prefix LINFlexD5_
Registers as LINFlexD0.

## LINFlexD6
Base 0x40084000; register names take the prefix LINFlexD6_
Registers as LINFlexD0.

## LINFlexD7
Base 0x40088000; register names take the prefix LINFlexD7_
Registers as LINFlexD0.

## LINFlexD8
Base 0x4008C000; register names take the prefix LINFlexD8_
Registers as LINFlexD0.

## LINFlexD9
Base 0x40090000; register names take the prefix LINFlexD9_
Registers as LINFlexD0.
